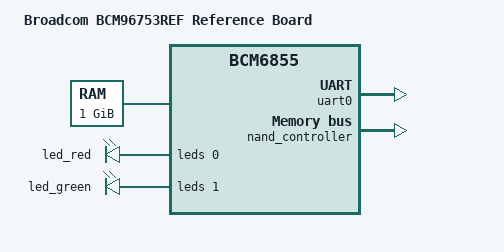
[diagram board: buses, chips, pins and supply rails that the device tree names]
// SPDX-License-Identifier: GPL-2.0+
/*
 * Copyright (C) 2022 Philippe Reynes <philippe.reynes@softathome.com>
 */

/dts-v1/;

#include "bcm6855.dtsi"

#include <dt-bindings/gpio/gpio.h>

/ {
	model = "Broadcom BCM96753REF Reference Board";
	compatible = "brcm,bcm96753ref", "brcm,bcm6855", "brcm,bcmbca";

	aliases {
		serial0 = &uart0;
	};

	chosen {
		stdout-path = "serial0:115200n8";
	};

	memory {
		device_type = "memory";
		reg = <0x0 0x40000000>;
	};
};

&uart0 {
	bootph-all;
	status = "okay";
};

&gpio0 {
	status = "okay";
};

&gpio1 {
	status = "okay";
};

&gpio2 {
	status = "okay";
};

&gpio3 {
	status = "okay";
};

&gpio4 {
	status = "okay";
};

&gpio5 {
	status = "okay";
};

&gpio6 {
	status = "okay";
};

&gpio7 {
	status = "okay";
};

&nand_controller {
	brcm,wp-not-connected;
	status = "okay";
};

&nandcs {
	nand-ecc-strength = <4>;
	nand-ecc-step-size = <512>;
	brcm,nand-oob-sector-size = <16>;
};

&leds {
	status = "okay";
	#address-cells = <1>;
	#size-cells = <0>;
	brcm,serial-led-en-pol;
	brcm,serial-led-data-ppol;

	led@0 {
		reg = <0>;
		label = "led_red";
	};

	led@1 {
		reg = <1>;
		label = "led_green";
	};
};
